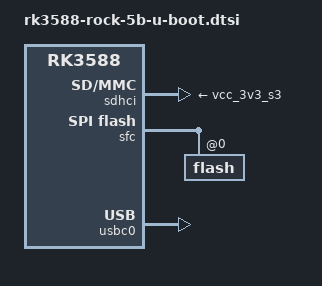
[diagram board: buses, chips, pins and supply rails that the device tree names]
// SPDX-License-Identifier: (GPL-2.0+ OR MIT)
/*
 * Copyright (c) 2023 Collabora Ltd.
 */

#include <dt-bindings/usb/pd.h>
#include "rk3588-u-boot.dtsi"

/ {
	leds {
		led_rgb_b {
			default-state = "on";
		};
	};
};

&fspim2_pins {
	bootph-pre-ram;
	bootph-some-ram;
};

&saradc {
	bootph-pre-ram;
	vdd-microvolts = <1800000>;
};

&sdhci {
	cap-mmc-highspeed;
	mmc-ddr-1_8v;
	mmc-hs200-1_8v;
	vmmc-supply = <&vcc_3v3_s3>;
	vqmmc-supply = <&vcc_1v8_s3>;
};

&sfc {
	flash@0 {
		bootph-pre-ram;
		bootph-some-ram;
	};
};

&usbc0 {
	status = "okay";
};
